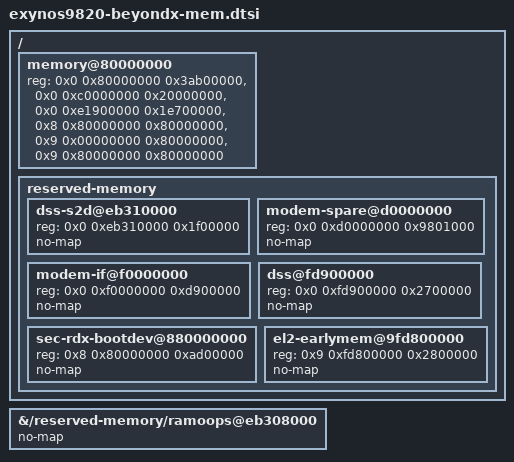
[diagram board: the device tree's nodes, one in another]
// SPDX-License-Identifier: GPL-2.0 OR BSD-3-Clause
/*
 * Galaxy S10 5G: all of its RAM, included by
 * scripts/build-boot.sh --device beyondx --mem.
 *
 * Added for OmonullOS, October 2026. Tested on the phone (bx11): 7121 MB
 * for Linux, 6 GB of tmpfs filled with copies of 1 GB of random data, all
 * read back intact; pstore still at 0xeb308000.
 *
 * Without this, Linux gets the two banks below 0xe0000000 (1177 MB). The
 * banks are the ones S-Boot writes into the stock kernel's tree
 * (stock/live/beyondx-twrp-boot.dts, read under TWRP): 0xbab00000-0xc0000000
 * and 0xe0000000-0xe1900000 are left out there too (secure world). Every
 * fixed region the stock tree reserves inside the four new banks is kept
 * away from Linux as well: the modem's, Samsung's ramdump and debug-snapshot
 * areas (S-Boot reads them after a reset) and the hypervisor's early memory.
 */

/ {
	memory@80000000 {
		reg = <0x0 0x80000000 0x3ab00000>,
		      <0x0 0xc0000000 0x20000000>,
		      <0x0 0xe1900000 0x1e700000>,
		      <0x8 0x80000000 0x80000000>,
		      <0x9 0x00000000 0x80000000>,
		      <0x9 0x80000000 0x80000000>;
	};

	reserved-memory {
		/* debug-snapshot log_s2d + log_arraydump, next to its log_pstore */
		dss-s2d@eb310000 {
			reg = <0x0 0xeb310000 0x1f00000>;
			no-map;
		};

		/* the S5100 side of the stock modem layout, up to 0xd9801000:
		 * modem_spare (CP linear workaround), modem_if2, cp2cp_shm and
		 * s5100_msi. Kept away from Linux before the LTE modem (S5000AP)
		 * runs, in case its firmware reaches any of it. */
		modem-spare@d0000000 {
			reg = <0x0 0xd0000000 0x9801000>;
			no-map;
		};

		/* modem_if + cp_ram_logging */
		modem-if@f0000000 {
			reg = <0x0 0xf0000000 0xd900000>;
			no-map;
		};

		/* debug-snapshot header .. log_kevents, up to 4 GB */
		dss@fd900000 {
			reg = <0x0 0xfd900000 0x2700000>;
			no-map;
		};

		sec-rdx-bootdev@880000000 {
			reg = <0x8 0x80000000 0xad00000>;
			no-map;
		};

		el2-earlymem@9fd800000 {
			reg = <0x9 0xfd800000 0x2800000>;
			no-map;
		};
	};
};

/*
 * pstore now sits inside Linux's memory: keep it out of the linear map, so
 * it stays mapped as I/O (uncached) and a reset loses nothing.
 */
&{/reserved-memory/ramoops@eb308000} {
	no-map;
};
